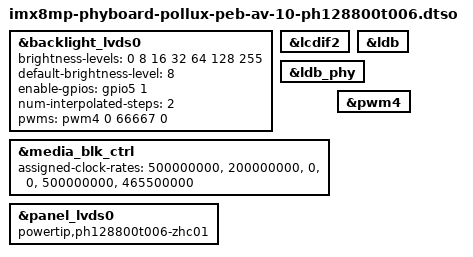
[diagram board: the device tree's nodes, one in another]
// SPDX-License-Identifier: GPL-2.0-or-later OR MIT
/*
 * Copyright (C) 2025 PHYTEC Messtechnik GmbH
 */

/dts-v1/;
/plugin/;

#include <dt-bindings/gpio/gpio.h>
#include <dt-bindings/clock/imx8mp-clock.h>
#include "imx8mp-phyboard-pollux-peb-av-10.dtsi"

&backlight_lvds0 {
	brightness-levels = <0 8 16 32 64 128 255>;
	default-brightness-level = <8>;
	enable-gpios = <&gpio5 1 GPIO_ACTIVE_HIGH>;
	num-interpolated-steps = <2>;
	pwms = <&pwm4 0 66667 0>;
	status = "okay";
};

&lcdif2 {
	status = "okay";
};

&ldb {
	status = "okay";
};

&ldb_phy {
	status = "okay";
};

&media_blk_ctrl {
	/*
	 * The LVDS panel on this device uses 66.5 MHz pixel clock,
	 * set IMX8MP_VIDEO_PLL1 to 66.5 * 7 = 465.5 MHz so the LDB
	 * serializer and LCDIFv3 scanout engine can reach accurate
	 * pixel clock of exactly 66.5 MHz.
	 */
	assigned-clock-rates = <500000000>, <200000000>,
			       <0>, <0>, <500000000>,
			       <465500000>;
};

&panel_lvds0 {
	compatible = "powertip,ph128800t006-zhc01";
	status = "okay";
};

&pwm4 {
	status = "okay";
};
